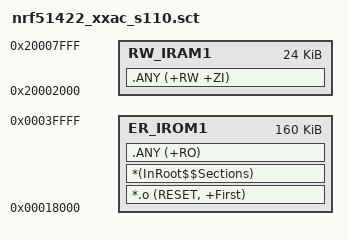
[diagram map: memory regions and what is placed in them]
; *************************************************************
; *** Scatter-Loading Description File generated by uVision ***
; *************************************************************

LR_IROM1 0x00018000 0x00028000  {    ; load region size_region
  ER_IROM1 0x00018000 0x00028000  {  ; load address = execution address
   *.o (RESET, +First)
   *(InRoot$$Sections)
   .ANY (+RO)
  }
  RW_IRAM1 0x20002000 0x00006000  {  ; RW data
   .ANY (+RW +ZI)
  }
}

